# ATmega128A register map
Vendor: Atmel; File version: 1.0
CPU: other r0p0, little endian, no MPU, no FPU, 4 interrupt priority bits
Registers are 8-bit, read-write, reset 0x0 unless marked. A register's access mark holds for its fields unless they carry their own. Offsets are from the block's base; [hi:lo] are bit positions.

## TC1 — Timer/Counter, 16-bit
Base 0x00000040
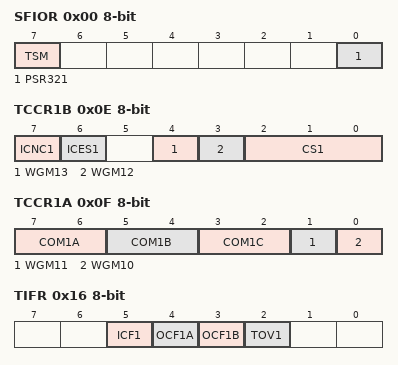
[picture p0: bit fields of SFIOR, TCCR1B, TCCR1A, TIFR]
0x00 SFIOR — Special Function IO Register
  [7] TSM — Timer/Counter Synchronization Mode
  [0] PSR321 — Prescaler Reset, T/C3, T/C2, T/C1
0x06 ICR1 16-bit (reset mask 0xFF) — Timer/Counter1 Input Capture Register Bytes
0x08 OCR1B 16-bit (reset mask 0xFF) — Timer/Counter1 Output Compare Register Bytes
0x0A OCR1A 16-bit (reset mask 0xFF) — Timer/Counter1 Output Compare Register Bytes
0x0C TCNT1 16-bit (reset mask 0xFF) — Timer/Counter1 Bytes
0x0E TCCR1B — Timer/Counter1 Control Register B
  [7] ICNC1 — Input Capture 1 Noise Canceler
  [6] ICES1 — Input Capture 1 Edge Select
  [4] WGM13 — Waveform Generation Mode
  [3] WGM12 — Waveform Generation Mode
  [2:0] CS1 — Clock Select1 bits
    0=No Clock Source (Stopped); 1=Running, No Prescaling; 2=Running, CLK/8; 3=Running, CLK/64; 4=Running, CLK/256; 5=Running, CLK/1024; 6=Running, ExtClk Tx Falling Edge; 7=Running, ExtClk Tx Rising Edge
0x0F TCCR1A — Timer/Counter1 Control Register A
  [7:6] COM1A — Compare Output Mode 1A, bits
  [5:4] COM1B — Compare Output Mode 1B, bits
  [3:2] COM1C — Compare Output Mode 1C, bits
  [1] WGM11 — Waveform Generation Mode
  [0] WGM10 — Waveform Generation Mode
0x16 TIFR — Timer/Counter Interrupt Flag register
  [5] ICF1 — Input Capture Flag 1
  [4] OCF1A — Output Compare Flag 1A
  [3] OCF1B — Output Compare Flag 1B
  [2] TOV1 — Timer/Counter1 Overflow Flag
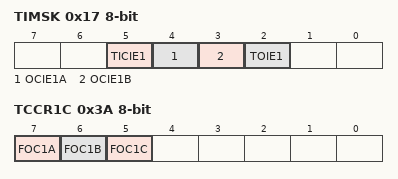
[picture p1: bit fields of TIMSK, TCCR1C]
0x17 TIMSK — Timer/Counter Interrupt Mask Register
  [5] TICIE1 — Timer/Counter1 Input Capture Interrupt Enable
  [4] OCIE1A — Timer/Counter1 Output CompareA Match Interrupt Enable
  [3] OCIE1B — Timer/Counter1 Output CompareB Match Interrupt Enable
  [2] TOIE1 — Timer/Counter1 Overflow Interrupt Enable
0x38 OCR1C 16-bit (reset mask 0xFF) — Timer/Counter1 Output Compare Register Bytes
0x3A TCCR1C — Timer/Counter1 Control Register C
  [7] FOC1A — Force Output Compare for channel A
  [6] FOC1B — Force Output Compare for channel B
  [5] FOC1C — Force Output Compare for channel C
0x3C ETIFR — Extended Timer/Counter Interrupt Flag register
  [0] OCF1C — Timer/Counter 1, Output Compare C Match Flag
0x3D ETIMSK — Extended Timer/Counter Interrupt Mask Register
  [0] OCIE1C — Timer/Counter 1, Output Compare Match C Interrupt Enable

## TC2 — Timer/Counter, 8-bit
Base 0x00000043
0x00 OCR2 — Output Compare Register
0x01 TCNT2 — Timer/Counter Register
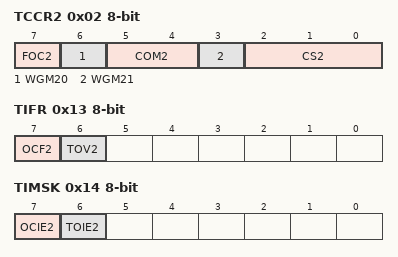
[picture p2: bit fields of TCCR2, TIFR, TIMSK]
0x02 TCCR2 — Timer/Counter Control Register
  [7] FOC2 — Force Output Compare
  [6] WGM20 — Wafeform Generation Mode
    0=Normal; 1=CTC
  [5:4] COM2 — Compare Match Output Mode
  [3] WGM21 — Waveform Generation Mode
  [2:0] CS2 — Clock Select
    0=No Clock Source (Stopped); 1=Running, No Prescaling; 2=Running, CLK/8; 3=Running, CLK/64; 4=Running, CLK/256; 5=Running, CLK/1024; 6=Running, ExtClk Tx Falling Edge; 7=Running, ExtClk Tx Rising Edge
0x13 TIFR — Timer/Counter Interrupt Flag Register
  [7] OCF2 — Output Compare Flag 2
  [6] TOV2 — Timer/Counter2 Overflow Flag
0x14 TIMSK
  [7] OCIE2, [6] TOIE2

## TC3 — Timer/Counter, 16-bit
Base 0x00000040
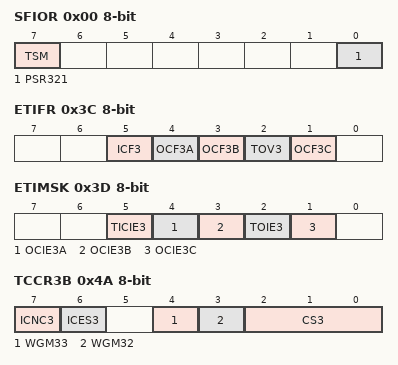
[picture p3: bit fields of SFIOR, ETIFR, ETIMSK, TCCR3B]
0x00 SFIOR — Special Function IO Register
  [7] TSM — Timer/Counter Synchronization Mode
  [0] PSR321 — Prescaler Reset, T/C3, T/C2, T/C1
0x3C ETIFR — Extended Timer/Counter Interrupt Flag register
  [5] ICF3 — Input Capture Flag 3
  [4] OCF3A — Output Compare Flag 3A
  [3] OCF3B — Output Compare Flag 3B
  [2] TOV3 — Timer/Counter3 Overflow Flag
  [1] OCF3C — Timer/Counter3 Output Compare C Match Flag
0x3D ETIMSK — Extended Timer/Counter Interrupt Mask Register
  [5] TICIE3 — Timer/Counter3 Input Capture Interrupt Enable
  [4] OCIE3A — Timer/Counter3 Output CompareA Match Interrupt Enable
  [3] OCIE3B — Timer/Counter3 Output CompareB Match Interrupt Enable
  [2] TOIE3 — Timer/Counter3 Overflow Interrupt Enable
  [1] OCIE3C — Timer/Counter3, Output Compare Match Interrupt Enable
0x40 ICR3 16-bit (reset mask 0xFF) — Timer/Counter3 Input Capture Register Bytes
0x42 OCR3C 16-bit (reset mask 0xFF) — Timer/Counter3 Output compare Register C Bytes
0x44 OCR3B 16-bit (reset mask 0xFF) — Timer/Counter3 Output Compare Register B Bytes
0x46 OCR3A 16-bit (reset mask 0xFF) — Timer/Counter3 Output Compare Register A Bytes
0x48 TCNT3 16-bit (reset mask 0xFF) — Timer/Counter3 Bytes
0x4A TCCR3B — Timer/Counter3 Control Register B
  [7] ICNC3 — Input Capture 3 Noise Canceler
  [6] ICES3 — Input Capture 3 Edge Select
  [4] WGM33 — Waveform Generation Mode
  [3] WGM32 — Waveform Generation Mode
  [2:0] CS3 — Clock Select3 bits
    0=No Clock Source (Stopped); 1=Running, No Prescaling; 2=Running, CLK/8; 3=Running, CLK/64; 4=Running, CLK/256; 5=Running, CLK/1024; 6=Running, ExtClk Tx Falling Edge; 7=Running, ExtClk Tx Rising Edge
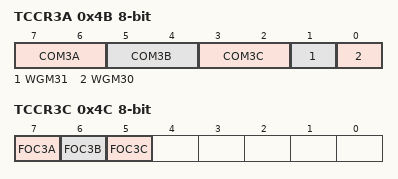
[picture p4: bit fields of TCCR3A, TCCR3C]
0x4B TCCR3A — Timer/Counter3 Control Register A
  [7:6] COM3A — Compare Output Mode 3A, bits
  [5:4] COM3B — Compare Output Mode 3B, bits
  [3:2] COM3C — Compare Output Mode 3C, bits
  [1] WGM31 — Waveform Generation Mode
  [0] WGM30 — Waveform Generation Mode
0x4C TCCR3C — Timer/Counter3 Control Register C
  [7] FOC3A — Force Output Compare for channel A
  [6] FOC3B — Force Output Compare for channel B
  [5] FOC3C — Force Output Compare for channel C

## TWI — Two Wire Serial Interface
Base 0x00000070
0x00 TWBR — TWI Bit Rate register
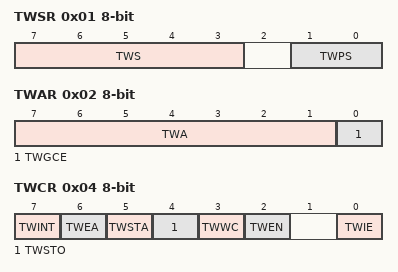
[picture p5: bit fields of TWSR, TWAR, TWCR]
0x01 TWSR — TWI Status Register
  [7:3] TWS — TWI Status
  [1:0] TWPS — TWI Prescaler
    0=1; 1=4; 2=16; 3=64
0x02 TWAR — TWI (Slave) Address register
  [7:1] TWA — TWI (Slave) Address register Bits
  [0] TWGCE — TWI General Call Recognition Enable Bit
0x03 TWDR — TWI Data register
0x04 TWCR — TWI Control Register
  [7] TWINT — TWI Interrupt Flag
  [6] TWEA — TWI Enable Acknowledge Bit
  [5] TWSTA — TWI Start Condition Bit
  [4] TWSTO — TWI Stop Condition Bit
  [3] TWWC — TWI Write Collition Flag
  [2] TWEN — TWI Enable Bit
  [0] TWIE — TWI Interrupt Enable

## USART0 — USART
Base 0x00000029
0x00 UBRR0L — USART Baud Rate Register Low Byte
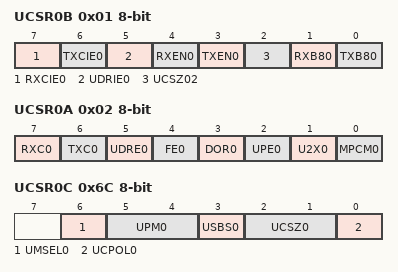
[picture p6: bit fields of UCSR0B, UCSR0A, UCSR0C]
0x01 UCSR0B — USART Control and Status Register B
  [7] RXCIE0 — RX Complete Interrupt Enable
  [6] TXCIE0 — TX Complete Interrupt Enable
  [5] UDRIE0 — USART Data register Empty Interrupt Enable
  [4] RXEN0 — Receiver Enable
  [3] TXEN0 — Transmitter Enable
  [2] UCSZ02 — Character Size
  [1] RXB80 — Receive Data Bit 8
  [0] TXB80 — Transmit Data Bit 8
0x02 UCSR0A — USART Control and Status Register A
  [7] RXC0 — USART Receive Complete
  [6] TXC0 — USART Transmitt Complete
  [5] UDRE0 — USART Data Register Empty
  [4] FE0 — Framing Error
  [3] DOR0 — Data overRun
  [2] UPE0 — Parity Error
  [1] U2X0 — Double the USART transmission speed
  [0] MPCM0 — Multi-processor Communication Mode
0x03 UDR0 — USART I/O Data Register
0x67 UBRR0H — USART Baud Rate Register Hight Byte
0x6C UCSR0C — USART Control and Status Register C
  [6] UMSEL0 — USART Mode Select
    0=Asynchronous Operation; 1=Synchronous Operation
  [5:4] UPM0 — Parity Mode Bits
    0=Disabled; 2=Enabled, Even Parity; 3=Enabled, Odd Parity
  [3] USBS0 — Stop Bit Select
    0=1-bit; 1=2-bit
  [2:1] UCSZ0 — Character Size
  [0] UCPOL0 — Clock Polarity

## USART1 — USART
Base 0x00000098
0x00 UBRR1H — USART Baud Rate Register Hight Byte
0x01 UBRR1L — USART Baud Rate Register Low Byte
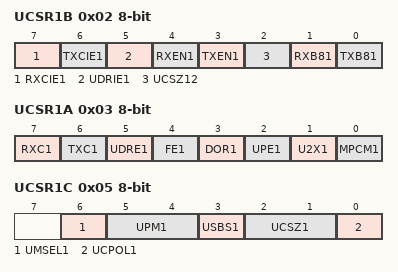
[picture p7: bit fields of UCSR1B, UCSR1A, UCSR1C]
0x02 UCSR1B — USART Control and Status Register B
  [7] RXCIE1 — RX Complete Interrupt Enable
  [6] TXCIE1 — TX Complete Interrupt Enable
  [5] UDRIE1 — USART Data register Empty Interrupt Enable
  [4] RXEN1 — Receiver Enable
  [3] TXEN1 — Transmitter Enable
  [2] UCSZ12 — Character Size
  [1] RXB81 — Receive Data Bit 8
  [0] TXB81 — Transmit Data Bit 8
0x03 UCSR1A — USART Control and Status Register A
  [7] RXC1 — USART Receive Complete
  [6] TXC1 — USART Transmitt Complete
  [5] UDRE1 — USART Data Register Empty
  [4] FE1 — Framing Error
  [3] DOR1 — Data overRun
  [2] UPE1 — Parity Error
  [1] U2X1 — Double the USART transmission speed
  [0] MPCM1 — Multi-processor Communication Mode
0x04 UDR1 — USART I/O Data Register
0x05 UCSR1C — USART Control and Status Register C
  [6] UMSEL1 — USART Mode Select
    0=Asynchronous Operation; 1=Synchronous Operation
  [5:4] UPM1 — Parity Mode Bits
    0=Disabled; 2=Enabled, Even Parity; 3=Enabled, Odd Parity
  [3] USBS1 — Stop Bit Select
    0=1-bit; 1=2-bit
  [2:1] UCSZ1 — Character Size
  [0] UCPOL1 — Clock Polarity

## WDT — Watchdog Timer
Base 0x00000041
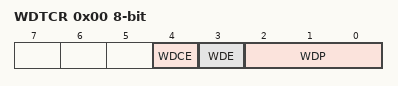
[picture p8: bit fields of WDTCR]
0x00 WDTCR — Watchdog Timer Control Register
  [4] WDCE — Watchdog Change Enable
  [3] WDE — Watch Dog Enable
  [2:0] WDP — Watch Dog Timer Prescaler bits
    0=Oscillator Cycles 16K; 1=Oscillator Cycles 32K; 2=Oscillator Cycles 64K; 3=Oscillator Cycles 128K; 4=Oscillator Cycles 256K; 5=Oscillator Cycles 512K; 6=Oscillator Cycles 1024K; 7=Oscillator Cycles 2048K
